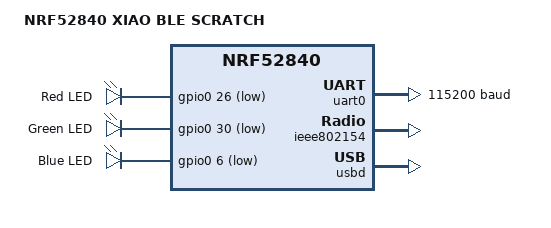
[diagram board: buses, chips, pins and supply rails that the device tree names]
/dts-v1/;

#include <nordic/nrf52840_qiaa.dtsi>
#include <nordic/nrf52840_partition_uf2_sdv7.dtsi>
#include "xiao_ble-pinctrl.dtsi"

/ {
	model = "NRF52840 XIAO BLE SCRATCH";
	compatible = "payatek,nrf52840_scratch";

	aliases {
		led0 = &led0;
		led1 = &led1;
		led2 = &led2;
	};

	chosen {
		zephyr,ieee802154 = &ieee802154;
	};

	leds {
		compatible = "gpio-leds";

		led0: led_0 {
			gpios = <&gpio0 26 GPIO_ACTIVE_LOW>;
			label = "Red LED";
		};

		led1: led_1 {
			gpios = <&gpio0 30 GPIO_ACTIVE_LOW>;
			label = "Green LED";
		};

		led2: led_2 {
			gpios = <&gpio0 6 GPIO_ACTIVE_LOW>;
			label = "Blue LED";
		};
	};
};

&gpiote {
	status = "okay";
};

&gpio0 {
	status = "okay";
};

&uart0 {
	compatible = "nordic,nrf-uarte";
	status = "okay";
	current-speed = <115200>;
	pinctrl-0 = <&uart0_default>;
	pinctrl-1 = <&uart0_sleep>;
	pinctrl-names = "default", "sleep";
};


&ieee802154 {
	status = "okay";
};

zephyr_udc0: &usbd {
	compatible = "nordic,nrf-usbd";
	status = "okay";
};

#include <../boards/common/usb/cdc_acm_serial.dtsi>
